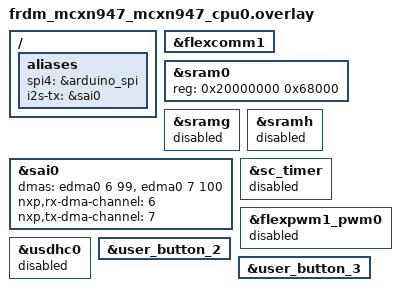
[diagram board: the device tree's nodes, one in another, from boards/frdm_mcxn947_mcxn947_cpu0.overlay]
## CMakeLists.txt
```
cmake_minimum_required(VERSION 3.20.0)
find_package(Zephyr REQUIRED HINTS $ENV{ZEPHYR_BASE})
project(zephyr_doom)

target_include_directories(app PRIVATE src/)
target_include_directories(app PRIVATE src/config)

target_sources(app PRIVATE
                src/main.c
                # Nordic-specific hardware drivers removed for portable core build:
                # src/n_qspi.c
                # src/n_fs.c
                # src/n_mem.c
                # src/n_buttons.c
                src/n_display.c
                # src/n_rjoy.c
                src/n_i2s.c
                src/n_i2s_sound.c
                src/portable_stubs.c
                src/deh_main.c
                src/deh_str.c
                src/doom/deh_misc.h
                src/doom/deh_misc.c
                src/d_event.c
                src/d_iwad.c
                src/d_mode.c
                src/d_loop.c
                src/i_timer.c
                src/i_system.c
                src/i_input.c
                src/i_video.c
                src/i_joystick.c
                src/i_sound.c
                src/m_argv.c
                src/m_bbox.c
                src/m_cheat.c
                src/m_config.c
                src/m_fixed.c
                src/m_misc.c
                src/m_controls.c
                src/net_client.c
                src/net_server.c
                src/tables.c
                src/v_diskicon.c
                src/v_video.c
                src/w_checksum.c
                src/w_file.c
                # src/w_file_fatfs.c  # disabled: usdhc0 shares pins with SAI0
                src/w_main.c
                src/w_wad.c
                src/z_native.c
                src/doom/am_map.c
                src/doom/doomstat.c
                src/doom/d_main.c
                src/doom/d_net.c
                src/doom/d_items.c
                src/doom/dstrings.c
                src/doom/f_wipe.c
                src/doom/f_finale.c
                src/doom/g_game.c
                src/doom/hu_lib.c
                src/doom/hu_stuff.c
                src/doom/info.c
                src/doom/m_menu.c
                src/doom/m_random.c
                src/doom/p_doors.c
                src/doom/p_ceilng.c
                src/doom/p_enemy.c
                src/doom/p_floor.c
                src/doom/p_lights.c
                src/doom/p_plats.c
                src/doom/p_telept.c
                src/doom/p_setup.c
                src/doom/p_sight.c
                src/doom/p_saveg.c
                src/doom/p_map.c
                src/doom/p_maputl.c
                src/doom/p_mobj.c
                src/doom/p_inter.c
                src/doom/p_tick.c
                src/doom/p_spec.c
                src/doom/p_switch.c
                src/doom/p_pspr.c
                src/doom/p_user.c
                src/doom/r_bsp.c
                src/doom/r_main.c
                src/doom/r_data.c
                src/doom/r_draw.c
                src/doom/r_plane.c
                src/doom/r_segs.c
                src/doom/r_sky.c
                src/doom/r_things.c
                src/doom/s_sound.c
                src/doom/st_lib.c
                src/doom/st_stuff.c
                src/doom/statdump.c
                src/doom/sounds.c
                src/doom/wi_stuff.c
                )


# set C version
set(CMAKE_C_STANDARD 89)

# set oldest CPP version
set(CMAKE_CXX_STANDARD  98)
```

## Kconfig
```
mainmenu "Zephyr Kernel Configuration"

# source "${ZEPHYR_BASE}/share/sysbuild/Kconfig"
source "Kconfig.zephyr"

module = DOOM_MAIN
module-str = doom_main
source "subsys/logging/Kconfig.template.log_config"

# Central UART seems to work even without this
# config NRF_DEFAULT_BLUETOOTH
# 	default y
```

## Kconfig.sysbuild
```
#
# Copyright (c) 2023 Nordic Semiconductor
#
# SPDX-License-Identifier: LicenseRef-Nordic-5-Clause
#

source "${ZEPHYR_BASE}/share/sysbuild/Kconfig"
# source "Kconfig.zephyr"

config NRF_DEFAULT_IPC_RADIO
	default y

config NETCORE_IPC_RADIO_BT_HCI_IPC
	default y
```

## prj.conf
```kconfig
## SD card filesystem disabled — usdhc0 shares pins with SAI0 (audio)
## WAD is in external flash, not on SD card
# CONFIG_DISK_DRIVERS is not set
# CONFIG_FILE_SYSTEM is not set
# CONFIG_DISK_ACCESS is not set
# CONFIG_FAT_FILESYSTEM_ELM is not set
# CONFIG_FS_FATFS_EXFAT is not set
# CONFIG_FS_FATFS_LFN is not set
# CONFIG_FS_FATFS_LFN_MODE_STACK is not set
CONFIG_SPI=y
CONFIG_GPIO=y

## Removed Nordic QSPI/XIP for portable core
# CONFIG_NRFX_QSPI is not set
CONFIG_XIP=y
# CONFIG_NORDIC_QSPI_NOR_XIP is not set
CONFIG_FLASH=y

CONFIG_MAIN_STACK_SIZE=4096

CONFIG_THREAD_RUNTIME_STATS=y
CONFIG_THREAD_RUNTIME_STATS_USE_TIMING_FUNCTIONS=y
CONFIG_TIMING_FUNCTIONS=y
CONFIG_CPU_LOAD=y
CONFIG_CPU_LOAD_LOG_PERIODICALLY=1000

CONFIG_DISPLAY=y
CONFIG_HEAP_MEM_POOL_SIZE=55000

CONFIG_SRAM_SIZE=416

## Bluetooth disabled in minimal build
# CONFIG_BT is not set

CONFIG_SYSTEM_WORKQUEUE_STACK_SIZE=2048

CONFIG_UART_INTERRUPT_DRIVEN=y
CONFIG_UART_LINE_CTRL=y

# Audio via Zephyr I2S
CONFIG_I2S=y
CONFIG_DMA_TCD_QUEUE_SIZE=4
CONFIG_LOG=y
CONFIG_LOG_MODE_IMMEDIATE=y
CONFIG_PRINTK=y
CONFIG_MAIN_THREAD_PRIORITY=4
```

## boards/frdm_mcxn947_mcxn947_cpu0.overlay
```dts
&flexcomm1 {
    status = "okay";
};

// Keep SPI DMA enabled for display performance.
// Synchronization in n_display.c ensures sync register accesses do not
// overlap with async framebuffer DMA transfers.

/ {
    aliases {
        spi4 = &arduino_spi;
        i2s-tx = &sai0;
    };
};

&sram0 {
    reg = < 0x20000000 0x68000 >;
};

&sramg {
    status = "disabled";
};

&sramh {
    status = "disabled";
};

/* I2S audio via SAI0 → PCM5102 DAC.
 * SAI0 pins: TXD0=PIO2_2, TX_BCLK=PIO2_6, TX_FS=PIO2_7.
 * These pins conflict with sc_timer, flexpwm1_pwm0, and usdhc0.
 * Also move SAI0 onto dedicated EDMA channels so it does not collide with
 * the display SPI DMA channels used by arduino_spi. */
&sai0 {
    status = "okay";
    dmas = <&edma0 6 99>, <&edma0 7 100>;
    dma-names = "rx", "tx";
    nxp,rx-dma-channel = <6>;
    nxp,tx-dma-channel = <7>;
};

&sc_timer {
    status = "disabled";
};

&flexpwm1_pwm0 {
    status = "disabled";
};

&usdhc0 {
    status = "disabled";
};

&user_button_2 {
    status = "okay";
};

&user_button_3 {
    status = "okay";
};
```

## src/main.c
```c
/*
 * Copyright (c) 2016 Intel Corporation
 *
 * SPDX-License-Identifier: Apache-2.0
 */

#ifdef CONFIG_FAT_FILESYSTEM_ELM
#include <ff.h>
#endif
#include <string.h>
#include <zephyr/device.h>
#include <zephyr/devicetree.h>
#include <zephyr/drivers/gpio.h>
#ifdef CONFIG_FAT_FILESYSTEM_ELM
#include <zephyr/fs/fs.h>
#endif
#include <zephyr/kernel.h>
#include <zephyr/logging/log.h>
// #include <zephyr/sd/sd.h>
#include <zephyr/storage/disk_access.h>

#include <zephyr/debug/cpu_load.h>

#include <zephyr/sys/printk.h>

extern uint32_t SystemCoreClock;

LOG_MODULE_REGISTER(doom_main, CONFIG_DOOM_MAIN_LOG_LEVEL);

/* Bluetooth control disabled in portable core build */

/* Forward declarations from original headers to avoid pulling Nordic-specific
 * dependencies */
void N_ButtonsInit(void);
void N_I2S_init(void);
void M_ArgvInit(void);
void D_DoomMain(void);

/* 1000 msec = 1 sec */
#define SLEEP_TIME_MS 1000

/* LED access not used in minimal build */

#define SD_ROOT_PATH "/SD:/"
#ifdef CONFIG_FAT_FILESYSTEM_ELM
/* Maximum length for path support by Windows file system */
#define PATH_MAX_LEN 260
#define K_SEM_OPER_TIMEOUT_MS 500
K_SEM_DEFINE(m_sem_sd_oper_ongoing, 1, 1);

void clock_initialization() { /* No-op for portable build */ }

static const char* sd_root_path = "/SD:";
static bool sd_init_success;

static FATFS fat_fs;

static struct fs_mount_t mnt_pt = {
    .type = FS_FATFS,
    .fs_data = &fat_fs,
};

int sd_card_init(void) {
    int ret;
    static const char* sd_dev = "SD";
    uint64_t sd_card_size_bytes;
    uint32_t sector_count;
    size_t sector_size;

    ret = disk_access_init(sd_dev);
    if (ret) {
        LOG_DBG("SD card init failed, please check if SD card inserted");
        return -ENODEV;
    }

    ret = disk_access_ioctl(sd_dev, DISK_IOCTL_GET_SECTOR_COUNT, &sector_count);
    if (ret) {
        LOG_ERR("Unable to get sector count");
        return ret;
    }

    LOG_DBG("Sector count: %d", sector_count);

    ret = disk_access_ioctl(sd_dev, DISK_IOCTL_GET_SECTOR_SIZE, &sector_size);
    if (ret) {
        LOG_ERR("Unable to get sector size");
        return ret;
    }

    LOG_DBG("Sector size: %d bytes", sector_size);

    sd_card_size_bytes = (uint64_t)sector_count * sector_size;

    LOG_INF("SD card volume size: %d MB", (uint32_t)(sd_card_size_bytes >> 20));

    mnt_pt.mnt_point = sd_root_path;

    ret = fs_mount(&mnt_pt);
    if (ret) {
        LOG_ERR("Mnt. disk failed, could be format issue. should be FAT/exFAT");
        return ret;
    }

    sd_init_success = true;

    return 0;
}

int sd_card_list_files(char const* const path, char* buf, size_t* buf_size) {
    int ret;
    struct fs_dir_t dirp;
    static struct fs_dirent entry;
    char abs_path_name[PATH_MAX_LEN + 1] = SD_ROOT_PATH;
    size_t used_buf_size = 0;

    if (k_sem_count_get(&m_sem_sd_oper_ongoing) <= 0) {
        LOG_ERR("SD operation ongoing");
        return -EPERM;
    }

    k_sem_take(&m_sem_sd_oper_ongoing, K_MSEC(K_SEM_OPER_TIMEOUT_MS));

    if (!sd_init_success) {
        k_sem_give(&m_sem_sd_oper_ongoing);
        return -ENODEV;
    }

    fs_dir_t_init(&dirp);

    if (path == NULL) {
        ret = fs_opendir(&dirp, sd_root_path);
        if (ret) {
            LOG_ERR("Open SD card root dir failed");
            k_sem_give(&m_sem_sd_oper_ongoing);
            return ret;
        }
    } else {
        if (strlen(path) > CONFIG_FS_FATFS_MAX_LFN) {
            LOG_ERR("Path is too long");
            k_sem_give(&m_sem_sd_oper_ongoing);
            // return -FR_INVALID_NAME;
            return -1;
        }

        strcat(abs_path_name, path);

        ret = fs_opendir(&dirp, abs_path_name);
        if (ret) {
            LOG_ERR("Open assigned path failed");
            k_sem_give(&m_sem_sd_oper_ongoing);
            return ret;
        }
    }

    while (1) {
        ret = fs_readdir(&dirp, &entry);
        if (ret) {
            k_sem_give(&m_sem_sd_oper_ongoing);
            return ret;
        }

        if (entry.name[0] == 0) {
            break;
        }

        if (buf != NULL) {
            size_t remaining_buf_size = *buf_size - used_buf_size;
            ssize_t len = snprintk(
                &buf[used_buf_size], remaining_buf_size, "[%s]\t%s\n",
                entry.type == FS_DIR_ENTRY_DIR ? "DIR " : "FILE", entry.name);

            if (len >= remaining_buf_size) {
                LOG_ERR("Failed to append to buffer, error: %d", len);
                k_sem_give(&m_sem_sd_oper_ongoing);
                return -EINVAL;
            }

            used_buf_size += len;
        }

        LOG_INF("[%s] %s", entry.type == FS_DIR_ENTRY_DIR ? "DIR " : "FILE",
                entry.name);
    }

    ret = fs_closedir(&dirp);
    if (ret) {
        LOG_ERR("Close SD card root dir failed");
        k_sem_give(&m_sem_sd_oper_ongoing);
        return ret;
    }

    *buf_size = used_buf_size;
    k_sem_give(&m_sem_sd_oper_ongoing);
    return 0;
}
#else
void clock_initialization() { /* No-op for portable build */ }
#endif /* CONFIG_FAT_FILESYSTEM_ELM */

int main(void) {
    LOG_INF("BOARD STARTING %s", CONFIG_BOARD);

    printk("CPU clock: %u Hz\n", SystemCoreClock);


    /* Minimal portable initialization */
    N_ButtonsInit();
    N_I2S_init();
    M_ArgvInit();

    /* Start DOOM */
    D_DoomMain();

    /* Idle forever */
    for (;;) {
        k_sleep(K_MSEC(SLEEP_TIME_MS));
    }

    return 0;
}
```

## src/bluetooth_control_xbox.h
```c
/* main.c - Application main entry point */

/*
 * Copyright (c) 2018 Nordic Semiconductor ASA
 *
 * SPDX-License-Identifier: LicenseRef-Nordic-5-Clause
 */

#include <bluetooth/gatt_dm.h>
#include <bluetooth/scan.h>
#include <bluetooth/services/hogp.h>
#include <errno.h>
#include <stddef.h>
#include <stdint.h>
#include <zephyr/bluetooth/bluetooth.h>
#include <zephyr/bluetooth/conn.h>
#include <zephyr/bluetooth/gatt.h>
#include <zephyr/bluetooth/hci.h>
#include <zephyr/bluetooth/uuid.h>
#include <zephyr/devicetree.h>
#include <zephyr/drivers/gpio.h>
#include <zephyr/kernel.h>
#include <zephyr/logging/log.h>
#include <zephyr/settings/settings.h>
#include <zephyr/sys/byteorder.h>
#include <zephyr/sys/printk.h>
#include <zephyr/types.h>

#include "d_event.h"
#include "m_controls.h"

#define RESET_TIMEOUT_MS 500

#define DEADZONE_X 8
#define DEADZONE_Y 8

static struct k_work_delayable reset_work;
static void reset_inputs(struct k_work *work) {
    printk("Resetting joystick and button states\n");

    event_t joystick_event;
    joystick_event.type = ev_joystick;
    joystick_event.data1 = 0;  // No buttons pressed
    joystick_event.data2 = 0;  // Joystick X reset
    joystick_event.data3 = 0;  // Joystick Y reset

    D_PostEvent(&joystick_event);
}

#define SW0_NODE DT_ALIAS(sw0)
static const struct gpio_dt_spec button =
    GPIO_DT_SPEC_GET_OR(SW0_NODE, gpios, {0});

static struct gpio_callback button_cb_data;
static struct bt_conn *default_conn;
static struct bt_hogp hogp;
static struct bt_conn *auth_conn;

static void hids_on_ready(struct k_work *work);
static K_WORK_DEFINE(hids_ready_work, hids_on_ready);

extern struct bt_gatt_dm {
    /* Connection object */
    struct bt_conn *conn;
    /* The user context */
    void *context;

    /* The discovery parameters used */
    struct bt_gatt_discover_params discover_params;
    /* Currently parsed attributes */
    struct bt_gatt_dm_attr attrs[CONFIG_BT_GATT_DM_MAX_ATTRS];
    /* Currently accessed attribute */
    size_t cur_attr_id;
    /* Flags with the status of the attributes */
    // ATOMIC_DEFINE(state_flags, STATE_NUM);

    /* The UUID of the service to discover. */
    union {
        struct bt_uuid uuid;
        struct bt_uuid_16 u16;
        struct bt_uuid_32 u32;
        struct bt_uuid_128 u128;
    } svc_uuid;

    /* Single-linked list of allocated chunks for user data */
    sys_slist_t chunk_list;
    /* The used length of the current chunk */
    size_t cur_chunk_len;

    /* The pointer to callback structure */
    const struct bt_gatt_dm_cb *callback;

    /* Indicates that services should be searched by the UUID. */
    bool search_svc_by_uuid;
};

static void scan_filter_match(struct bt_scan_device_info *device_info,
                              struct bt_scan_filter_match *filter_match,
                              bool connectable) {
    char addr[BT_ADDR_LE_STR_LEN];

    if (!filter_match->uuid.match || (filter_match->uuid.count != 1)) {
        printk("Invalid device connected\n");

        return;
    }

    const struct bt_uuid *uuid = filter_match->uuid.uuid[0];

    bt_addr_le_to_str(device_info->recv_info->addr, addr, sizeof(addr));

    printk("Filters matched on UUID 0x%04x.\nAddress: %s connectable: %s\n",
           BT_UUID_16(uuid)->val, addr, connectable ? "yes" : "no");
}

static void scan_connecting_error(struct bt_scan_device_info *device_info) {
    printk("Connecting failed\n");
}

static void scan_connecting(struct bt_scan_device_info *device_info,
                            struct bt_conn *conn) {
    default_conn = bt_conn_ref(conn);
}
/** .. include_startingpoint_scan_rst */
static void scan_filter_no_match(struct bt_scan_device_info *device_info,
                                 bool connectable) {
    int err;
    struct bt_conn *conn;
    char addr[BT_ADDR_LE_STR_LEN];

    if (device_info->recv_info->adv_type == BT_GAP_ADV_TYPE_ADV_DIRECT_IND) {
        bt_addr_le_to_str(device_info->recv_info->addr, addr, sizeof(addr));
        printk("Direct advertising received from %s\n", addr);
        bt_scan_stop();

        err = bt_conn_le_create(device_info->recv_info->addr,
                                BT_CONN_LE_CREATE_CONN, device_info->conn_param,
                                &conn);

        if (!err) {
            default_conn = bt_conn_ref(conn);
            bt_conn_unref(conn);
        }
    }
}
/** .. include_endpoint_scan_rst */
BT_SCAN_CB_INIT(scan_cb, scan_filter_match, scan_filter_no_match,
                scan_connecting_error, scan_connecting);

// for XBOX Gamepad
void convert_uuid128_to_uuid16_services(struct bt_gatt_dm *dm) {
    char str[37];
    int i = 0;

    while (dm->attrs[i + 1].handle != 0x0000) {
        if (!bt_uuid_cmp(dm->attrs[i].uuid,
                         BT_UUID_DECLARE_128(BT_UUID_128_ENCODE(
                             BT_UUID_HIDS_INFO_VAL, 0, 0, 0, 0)))) {
            dm->attrs[i].uuid->type = BT_UUID_TYPE_16;
            BT_UUID_16(dm->attrs[i].uuid)->val = BT_UUID_HIDS_INFO_VAL;
        }

        else if (!bt_uuid_cmp(dm->attrs[i].uuid,
                              BT_UUID_DECLARE_128(BT_UUID_128_ENCODE(
                                  BT_UUID_HIDS_CTRL_POINT_VAL, 0, 0, 0, 0)))) {
            dm->attrs[i].uuid->type = BT_UUID_TYPE_16;
            BT_UUID_16(dm->attrs[i].uuid)->val = BT_UUID_HIDS_CTRL_POINT_VAL;
        }

        else if (!bt_uuid_cmp(dm->attrs[i].uuid,
                              BT_UUID_DECLARE_128(BT_UUID_128_ENCODE(
                                  BT_UUID_HIDS_REPORT_MAP_VAL, 0, 0, 0, 0)))) {
            dm->attrs[i].uuid->type = BT_UUID_TYPE_16;
            BT_UUID_16(dm->attrs[i].uuid)->val = BT_UUID_HIDS_REPORT_MAP_VAL;
        }

        else if (!bt_uuid_cmp(dm->attrs[i].uuid,
                              BT_UUID_DECLARE_128(BT_UUID_128_ENCODE(
                                  BT_UUID_HIDS_REPORT_VAL, 0, 0, 0, 0)))) {
            dm->attrs[i].uuid->type = BT_UUID_TYPE_16;
            BT_UUID_16(dm->attrs[i].uuid)->val = BT_UUID_HIDS_REPORT_VAL;
            BT_UUID_16(dm->attrs[11].uuid)->val =
                BT_UUID_HIDS_REPORT_VAL;  // hardcoded for XBOX
        }

        bt_uuid_to_str(dm->attrs[i].uuid, str, sizeof(str));
        printk("\tUUID[%d]: 0x%s\t\n", i, str);

        i++;
    }
}

static void discovery_completed_cb(struct bt_gatt_dm *dm, void *context) {
    int err;

    printk("The discovery procedure succeeded\n");
    printk(
        "\nFor XBOX controllers, you need to manually exit pairing mode or "
        "wait for the timeout\n\n");

    convert_uuid128_to_uuid16_services(
        dm);  // need convert some UUID128 into UUID16 (for XBOX Controller)

    bt_gatt_dm_data_print(dm);

    err = bt_hogp_handles_assign(dm, &hogp);

    if (err) {
        printk("Could not init HIDS client object, error: %d\n", err);
    }

    err = bt_gatt_dm_data_release(dm);
    if (err) {
        printk(
            "Could not release the discovery data, error "
            "code: %d\n",
            err);
    }
}

static void discovery_service_not_found_cb(struct bt_conn *conn,
                                           void *context) {
    printk("The service could not be found during the discovery\n");
}

static void discovery_error_found_cb(struct bt_conn *conn, int err,
                                     void *context) {
    printk("The discovery procedure failed with %d\n", err);
}

static const struct bt_gatt_dm_cb discovery_cb = {
    .completed = discovery_completed_cb,
    .service_not_found = discovery_service_not_found_cb,
    .error_found = discovery_error_found_cb,
};

static void gatt_discover(struct bt_conn *conn) {
    int err;

    if (conn != default_conn) {
        return;
    }

    err = bt_gatt_dm_start(conn, BT_UUID_HIDS, &discovery_cb, NULL);
    if (err) {
        printk(
            "could not start the discovery procedure, error "
            "code: %d\n",
            err);
    }
}

static void connected(struct bt_conn *conn, uint8_t conn_err) {
    int err;
    char addr[BT_ADDR_LE_STR_LEN];

    bt_addr_le_to_str(bt_conn_get_dst(conn), addr, sizeof(addr));

    if (conn_err) {
        printk("Failed to connect to %s (%u)\n", addr, conn_err);
        if (conn == default_conn) {
            bt_conn_unref(default_conn);
            default_conn = NULL;

            /* This demo doesn't require active scan */
            err = bt_scan_start(BT_SCAN_TYPE_SCAN_ACTIVE);
            if (err) {
                printk("Scanning failed to start (err %d)\n", err);
            }
        }

        return;
    }

    printk("Connected: %s\n", addr);

    err = bt_conn_set_security(conn, BT_SECURITY_L2);
    if (err) {
        printk("Failed to set security: %d\n", err);

        gatt_discover(conn);
    }
}

static void disconnected(struct bt_conn *conn, uint8_t reason) {
    char addr[BT_ADDR_LE_STR_LEN];
    int err;

    bt_addr_le_to_str(bt_conn_get_dst(conn), addr, sizeof(addr));

    if (auth_conn) {
        bt_conn_unref(auth_conn);
        auth_conn = NULL;
    }

    printk("Disconnected: %s (reason %u)\n", addr, reason);

    if (bt_hogp_assign_check(&hogp)) {
        printk("HIDS client active - releasing");
        bt_hogp_release(&hogp);
    }

    if (default_conn != conn) {
        return;
    }

    bt_conn_unref(default_conn);
    default_conn = NULL;

    /* This demo doesn't require active scan */
    err = bt_scan_start(BT_SCAN_TYPE_SCAN_ACTIVE);
    if (err) {
        printk("Scanning failed to start (err %d)\n", err);
    }
}

static void security_changed(struct bt_conn *conn, bt_security_t level,
                             enum bt_security_err err) {
    char addr[BT_ADDR_LE_STR_LEN];

    bt_addr_le_to_str(bt_conn_get_dst(conn), addr, sizeof(addr));

    if (!err) {
        printk("Security changed: %s level %u\n", addr, level);
    } else {
        printk("Security failed: %s level %u err %d\n", addr, level, err);
    }

    gatt_discover(conn);
}

BT_CONN_CB_DEFINE(conn_callbacks) = {.connected = connected,
                                     .disconnected = disconnected,
                                     .security_changed = security_changed};

static void scan_init(void) {
    int err;

    struct bt_scan_init_param scan_init = {
        .connect_if_match = 1,
        .scan_param = NULL,
        .conn_param = BT_LE_CONN_PARAM_DEFAULT};

    bt_scan_init(&scan_init);
    bt_scan_cb_register(&scan_cb);

    err = bt_scan_filter_add(BT_SCAN_FILTER_TYPE_UUID, BT_UUID_HIDS);
    if (err) {
        printk("Scanning filters cannot be set (err %d)\n", err);

        return;
    }

    err = bt_scan_filter_enable(BT_SCAN_UUID_FILTER, false);
    if (err) {
        printk("Filters cannot be turned on (err %d)\n", err);
    }
}

static uint8_t hogp_notify_cb(struct bt_hogp *hogp,
                              struct bt_hogp_rep_info *rep, uint8_t err,
                              const uint8_t *data) {
    static bool prev_dpad_up = false;
    static bool prev_dpad_down = false;
    static bool prev_button_back = false;
    static bool prev_button_start = false;
    static event_t prev_joystick_event;

    if (!data) {
        return BT_GATT_ITER_STOP;
    }

    // uint8_t size = bt_hogp_rep_size(rep);
    // uint8_t i;
    // printk("Notification, id: %u, size: %u, data:", bt_hogp_rep_id(rep), size);

    // for (i = 0; i < size; ++i) {
    //     printk(" 0x%x", data[i]);
    // }
    // printk("\n");

    event_t joystick_event;
    event_t keyboard_event;
    joystick_event.type = ev_joystick;
    keyboard_event.type = ev_keydown;

    bool dpad_up = data[12] == 0x01;
    bool dpad_down = data[12] == 0x05;
    bool button_A = data[13] == 0x01;
    bool button_B = data[13] == 0x02;
    bool button_X = data[13] == 0x08;
    bool button_Y = data[13] == 0x10;
    bool button_back = data[14] == 0x04;
    bool button_start = data[14] == 0x08;
    joystick_event.data1 =
        (button_A << 4) | (button_B << 5) | (button_X << 2) | (button_Y << 3);

    // Left joystick used for movement and turning
    int32_t leftJoyX = (data[1] << 8 | data[0]);
    int32_t leftJoyY = (data[3] << 8 | data[2]);

    leftJoyX = ((leftJoyX - 32767) / (double)32767) * 65;
    leftJoyY = ((leftJoyY - 32767) / (double)32767) * 65;
    if (leftJoyX > -DEADZONE_X && leftJoyX < DEADZONE_X) {
        leftJoyX = 0;
    }
    if (leftJoyY > -DEADZONE_Y && leftJoyY < DEADZONE_Y) {
        leftJoyY = 0;
    }

    joystick_event.data2 = leftJoyX;
    joystick_event.data3 = leftJoyY;

    // Used for strafing
    int16_t LT = data[8];
    int16_t RT = data[10];

    if (LT > 5) {
        joystick_event.data4 = -LT;
    } else if (RT > 5) {
        joystick_event.data4 = RT;
    } else {
        joystick_event.data4 = 0;
    }

    if (joystick_event.data1 != prev_joystick_event.data1 ||
        joystick_event.data2 != prev_joystick_event.data2 ||
        joystick_event.data3 != prev_joystick_event.data3 ||
        joystick_event.data4 != prev_joystick_event.data4 ||
        joystick_event.data5 != prev_joystick_event.data5) {
        D_PostEvent(&joystick_event);
        prev_joystick_event = joystick_event;
    }
    if (dpad_up && !prev_dpad_up) {
        keyboard_event.data1 = key_up;
        D_PostEvent(&keyboard_event);
    }
    if (dpad_down && !prev_dpad_down) {
        keyboard_event.data1 = key_down;
        D_PostEvent(&keyboard_event);
    }
    if (button_back && !prev_button_back) {
        keyboard_event.data1 = key_map_toggle;
        D_PostEvent(&keyboard_event);
    }
    if (button_start && !prev_button_start) {
        keyboard_event.data1 = key_menu_activate;
        D_PostEvent(&keyboard_event);
    }

    prev_dpad_up = dpad_up;
    prev_dpad_down = dpad_down;
    prev_button_back = button_back;
    prev_button_start = button_start;

    // k_work_reschedule(&reset_work, K_MSEC(RESET_TIMEOUT_MS));

    return BT_GATT_ITER_CONTINUE;
}

static void hogp_ready_cb(struct bt_hogp *hogp) {
    k_work_submit(&hids_ready_work);
}

static void hids_on_ready(struct k_work *work) {
    int err;
    struct bt_hogp_rep_info *rep = NULL;

    printk("HIDS is ready to work\n");

    while (NULL != (rep = bt_hogp_rep_next(&hogp, rep))) {
        if (bt_hogp_rep_type(rep) == BT_HIDS_REPORT_TYPE_INPUT) {
            printk("Subscribe to report id: %u\n", bt_hogp_rep_id(rep));
            err = bt_hogp_rep_subscribe(&hogp, rep, hogp_notify_cb);
            if (err) {
                printk("Subscribe error (%d)\n", err);
            }
        }
    }
}

static void hogp_prep_fail_cb(struct bt_hogp *hogp, int err) {
    printk("ERROR: HIDS client preparation failed!\n");
}

/* HIDS client initialization parameters */
static const struct bt_hogp_init_params hogp_init_params = {
    .ready_cb = hogp_ready_cb,
    .prep_error_cb = hogp_prep_fail_cb,
};

void button_pressed(const struct device *dev, struct gpio_callback *cb,
                    uint32_t pins) {
    printk("Button Pressed\n");

    if (auth_conn) {
        bt_conn_auth_passkey_confirm(auth_conn);
        printk("Numeric Match, conn %p\n", auth_conn);
    }

    return;
}

static void auth_passkey_display(struct bt_conn *conn, unsigned int passkey) {
    char addr[BT_ADDR_LE_STR_LEN];

    bt_addr_le_to_str(bt_conn_get_dst(conn), addr, sizeof(addr));

    printk("Passkey for %s: %06u\n", addr, passkey);
}

static void auth_passkey_confirm(struct bt_conn *conn, unsigned int passkey) {
    char addr[BT_ADDR_LE_STR_LEN];

    auth_conn = bt_conn_ref(conn);

    bt_addr_le_to_str(bt_conn_get_dst(conn), addr, sizeof(addr));

    printk("Passkey for %s: %06u\n", addr, passkey);
    printk("Press Button 1 to confirm, Button 2 to reject.\n");
}

static void auth_cancel(struct bt_conn *conn) {
    char addr[BT_ADDR_LE_STR_LEN];

    bt_addr_le_to_str(bt_conn_get_dst(conn), addr, sizeof(addr));

    printk("Pairing cancelled: %s\n", addr);
}

static void pairing_complete(struct bt_conn *conn, bool bonded) {
    char addr[BT_ADDR_LE_STR_LEN];

    bt_addr_le_to_str(bt_conn_get_dst(conn), addr, sizeof(addr));

    printk("Pairing completed: %s, bonded: %d\n", addr, bonded);
}

static void pairing_failed(struct bt_conn *conn, enum bt_security_err reason) {
    char addr[BT_ADDR_LE_STR_LEN];

    bt_addr_le_to_str(bt_conn_get_dst(conn), addr, sizeof(addr));

    printk("Pairing failed conn: %s, reason %d\n", addr, reason);
}

static struct bt_conn_auth_cb conn_auth_callbacks = {
    .passkey_display = auth_passkey_display,
    .passkey_confirm = auth_passkey_confirm,
    .cancel = auth_cancel,
};

static struct bt_conn_auth_info_cb conn_auth_info_callbacks = {
    .pairing_complete = pairing_complete, .pairing_failed = pairing_failed};

int bluetooth_main_xbox(void) {
    int err;

    printk("Starting Bluetooth Central HIDS example\n");

    bt_hogp_init(&hogp, &hogp_init_params);

    err = bt_conn_auth_cb_register(&conn_auth_callbacks);
    if (err) {
        printk("failed to register authorization callbacks.\n");
        return 0;
    }

    err = bt_conn_auth_info_cb_register(&conn_auth_info_callbacks);
    if (err) {
        printk("Failed to register authorization info callbacks.\n");
        return 0;
    }

    err = bt_enable(NULL);
    if (err) {
        printk("Bluetooth init failed (err %d)\n", err);
        return 0;
    }

    printk("Bluetooth initialized\n");

    // if (IS_ENABLED(CONFIG_SETTINGS)) {
    //     settings_load();
    // }

    scan_init();

    if (!gpio_is_ready_dt(&button)) {
        printk("Error: button device %s is not ready\n", button.port->name);
        return 0;
    }

    err = gpio_pin_configure_dt(&button, GPIO_INPUT);
    if (err != 0) {
        printk("Error %d: failed to configure %s pin %d\n", err,
               button.port->name, button.pin);
        return 0;
    }

    err = gpio_pin_interrupt_configure_dt(&button, GPIO_INT_EDGE_TO_ACTIVE);
    if (err != 0) {
        printk("Error %d: failed to configure interrupt on %s pin %d\n", err,
               button.port->name, button.pin);
        return 0;
    }

    gpio_init_callback(&button_cb_data, button_pressed, BIT(button.pin));
    gpio_add_callback(button.port, &button_cb_data);

    k_work_init_delayable(&reset_work, reset_inputs);

    err = bt_scan_start(BT_SCAN_TYPE_SCAN_ACTIVE);
    if (err) {
        printk("Scanning failed to start (err %d)\n", err);
        return 0;
    }

    printk("Scanning successfully started\n");

    return 0;
}
```

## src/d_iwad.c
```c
//
// Copyright(C) 2005-2014 Simon Howard
//
// This program is free software; you can redistribute it and/or
// modify it under the terms of the GNU General Public License
// as published by the Free Software Foundation; either version 2
// of the License, or (at your option) any later version.
//
// This program is distributed in the hope that it will be useful,
// but WITHOUT ANY WARRANTY; without even the implied warranty of
// MERCHANTABILITY or FITNESS FOR A PARTICULAR PURPOSE.  See the
// GNU General Public License for more details.
//
// DESCRIPTION:
//     Search for and locate an IWAD file, and initialize according
//     to the IWAD type.
//

#include <stdio.h>
#include <stdlib.h>
#include <ctype.h>
#include <string.h>
#ifndef SEGGER
#include <strings.h>
#endif

#include "deh_str.h"
#include "doomkeys.h"
#include "d_iwad.h"
#include "i_system.h"
#include "m_argv.h"
#include "m_config.h"
#include "m_misc.h"
#include "w_wad.h"
#include "z_zone.h"

#include "n_mem.h"
#include "n_fs.h"

static const iwad_t iwads[] =
{
    { "doom.wad",     doom,      retail,     "Doom" },
    { "doom1.wad",    doom,      shareware,  "Doom Shareware" },
    { "doom2.wad",    doom2,     commercial, "Doom II" },
    /*
    { "plutonia.wad", pack_plut, commercial, "Final Doom: Plutonia Experiment" },
    { "tnt.wad",      pack_tnt,  commercial, "Final Doom: TNT: Evilution" },
    { "chex.wad",     pack_chex, retail,     "Chex Quest" },
    { "hacx.wad",     pack_hacx, commercial, "Hacx" },
    { "freedm.wad",   doom2,     commercial, "FreeDM" },
    { "freedoom2.wad", doom2,    commercial, "Freedoom: Phase 2" },
    { "freedoom1.wad", doom,     retail,     "Freedoom: Phase 1" },
    { "heretic.wad",  heretic,   retail,     "Heretic" },
    { "heretic1.wad", heretic,   shareware,  "Heretic Shareware" },
    { "hexen.wad",    hexen,     commercial, "Hexen" },
    //{ "strife0.wad",  strife,    commercial, "Strife" }, // haleyjd: STRIFE-FIXME
    { "strife1.wad",  strife,    commercial, "Strife" },*/
};

// Array of locations to search for IWAD files
//
// "128 IWAD search directories should be enough for anybody".

/* NRFD-TODO?
#define MAX_IWAD_DIRS 128

static boolean iwad_dirs_built = false;
static char *iwad_dirs[MAX_IWAD_DIRS];
static int num_iwad_dirs = 0;
*/

static void AddIWADDir(char *dir)
{
    /* NRFD_TODO?
    if (num_iwad_dirs < MAX_IWAD_DIRS)
    {
        iwad_dirs[num_iwad_dirs] = dir;
        ++num_iwad_dirs;
    }
    */
}


// Check if the specified directory contains the specified IWAD
// file, returning the full path to the IWAD if found, or NULL
// if not found.

static char *CheckDirectoryHasIWAD(char *dir, char *iwadname)
{
    char *filename;
    char *probe;

    // As a special case, the "directory" may refer directly to an
    // IWAD file if the path comes from DOOMWADDIR or DOOMWADPATH.

    // probe = M_FileCaseExists(dir);
    // if (DirIsFile(dir, iwadname) && probe != NULL)
    // {
    //     return probe;
    // }

    // Construct the full path to the IWAD if it is located in
    // this directory, and check if it exists.

/* NRFD-TODO?
    if (!strcmp(dir, "."))
    {
        filename = M_StringDuplicate(iwadname);
    }
    else
    {
        filename = M_StringJoin(dir, DIR_SEPARATOR_S, iwadname, NULL);
    }

    probe = M_FileCaseExists(filename);
    if (probe != NULL)
    {
        return probe;
    }

    free(filename);
    */
    probe = M_FileCaseExists(iwadname);
    if (probe != NULL)
    {
        return probe;
    }

    return NULL;
}

// Search a directory to try to find an IWAD
// Returns the location of the IWAD if found, otherwise NULL.

static char *SearchDirectoryForIWAD(char *dir, int mask, GameMission_t *mission)
{
    char *filename;
    size_t i;

    for (i=0; i<arrlen(iwads); ++i)
    {
        if (((1 << iwads[i].mission) & mask) == 0)
        {
            continue;
        }

        filename = CheckDirectoryHasIWAD(dir, DEH_String(iwads[i].name));

        if (filename != NULL)
        {
            *mission = iwads[i].mission;

            return filename;
        }
    }

    return NULL;
}

// When given an IWAD with the '-iwad' parameter,
// attempt to identify it by its name.

static GameMission_t IdentifyIWADByName(char *name, int mask)
{
    size_t i;
    GameMission_t mission;
    char *p;

    p = strrchr(name, DIR_SEPARATOR);

    if (p != NULL)
    {
        name = p + 1;
    }

    mission = none;

    for (i=0; i<arrlen(iwads); ++i)
    {
        // Check if the filename is this IWAD name.

        // Only use supported missions:

        if (((1 << iwads[i].mission) & mask) == 0)
            continue;

        // Check if it ends in this IWAD name.

        if (!strcasecmp(name, iwads[i].name))
        {
            mission = iwads[i].mission;
            break;
        }
    }

    return mission;
}


//
// Build a list of IWAD files
//

static void BuildIWADDirList(void)
{
    return; /* NRFD-TODO?
    char *env;

    if (iwad_dirs_built)
    {
        return;
    }

    // Only look in root
    AddIWADDir("");
    */

}

//
// Searches WAD search paths for an WAD with a specific filename.
//
char *D_FindWADByName(char *name)
{
    char *path;
    char *probe;
    int i;

    // Absolute path?

    probe = M_FileCaseExists(name);
    if (probe != NULL)
    {
        return probe;
    }

    BuildIWADDirList();

    // Search through all IWAD paths for a file with the given name.
    /* NRFD-TODO?
    for (i=0; i<num_iwad_dirs; ++i)
    {
        // As a special case, if this is in DOOMWADDIR or DOOMWADPATH,
        // the "directory" may actually refer directly to an IWAD
        // file.
        probe = M_FileCaseExists(iwad_dirs[i]);
        if (DirIsFile(iwad_dirs[i], name) && probe != NULL)
        {
            return probe;
        }

        // Construct a string for the full path

        path = M_StringJoin(iwad_dirs[i], DIR_SEPARATOR_S, name, NULL);

        probe = M_FileCaseExists(path);
        if (probe != NULL)
        {
            return probe;
        }

        free(path);
    }
    */

    probe = M_FileCaseExists(name);
    if (probe != NULL)
    {
        return probe;
    }


    // File not found
    return NULL;
}

//
// D_TryWADByName
//
// Searches for a WAD by its filename, or passes through the filename
// if not found.
//

char *D_TryFindWADByName(char *filename)
{
    char *result;

    result = D_FindWADByName(filename);

    if (result != NULL)
    {
        return result;
    }
    else
    {
        return filename;
    }
}

//
// FindIWAD
// Checks availability of IWAD files by name,
// to determine whether registered/commercial features
// should be executed (notably loading PWADs).
//

char *D_FindIWAD(int mask, GameMission_t *mission)
{
    char *result;
    char *iwadfile;
    int iwadparm;
    int i;

    // Check for the -iwad parameter

    //!
    // Specify an IWAD file to use.
    //
    // @arg <file>
    //

    iwadparm = M_CheckParmWithArgs("-iwad", 1);

    if (iwadparm)
    {
        // Search through IWAD dirs for an IWAD with the given name.

        iwadfile = myargv[iwadparm + 1];

        result = D_FindWADByName(iwadfile);

        if (result == NULL)
        {
            I_Error("IWAD file '%s' not found!", iwadfile);
        }

        *mission = IdentifyIWADByName(result, mask);
    }
    else
    {
        // Search through the list and look for an IWAD

        result = NULL;

        /* NRFD-TODO?
        BuildIWADDirList();

        for (i=0; result == NULL && i<num_iwad_dirs; ++i)
        {
            result = SearchDirectoryForIWAD(iwad_dirs[i], mask, mission);
        }
        */
        result = SearchDirectoryForIWAD("", mask, mission);
    }

    return result;
}

// Find all IWADs in the IWAD search path matching the given mask.

const iwad_t **D_FindAllIWADs(int mask)
{
    const iwad_t **result;
    int result_len;
    char *filename;
    int i;

    result = N_malloc(sizeof(iwad_t *) * (arrlen(iwads) + 1));
    result_len = 0;

    // Try to find all IWADs

    for (i=0; i<arrlen(iwads); ++i)
    {
        if (((1 << iwads[i].mission) & mask) == 0)
        {
            continue;
        }

        filename = D_FindWADByName(iwads[i].name);

        if (filename != NULL)
        {
            result[result_len] = &iwads[i];
            ++result_len;
        }
    }

    // End of list

    result[result_len] = NULL;

    return result;
}

//
// Get the IWAD name used for savegames.
//

char *D_SaveGameIWADName(GameMission_t gamemission)
{
    size_t i;

    // Determine the IWAD name to use for savegames.
    // This determines the directory the savegame files get put into.
    //
    // Note that we match on gamemission rather than on IWAD name.
    // This ensures that doom1.wad and doom.wad saves are stored
    // in the same place.

    for (i=0; i<arrlen(iwads); ++i)
    {
        if (gamemission == iwads[i].mission)
        {
            return iwads[i].name;
        }
    }

    // Default fallback:

    return "unknown.wad";
}

char *D_SuggestIWADName(GameMission_t mission, GameMode_t mode)
{
    int i;

    for (i = 0; i < arrlen(iwads); ++i)
    {
        if (iwads[i].mission == mission && iwads[i].mode == mode)
        {
            return iwads[i].name;
        }
    }

    return "unknown.wad";
}

char *D_SuggestGameName(GameMission_t mission, GameMode_t mode)
{
    int i;

    for (i = 0; i < arrlen(iwads); ++i)
    {
        if (iwads[i].mission == mission
         && (mode == indetermined || iwads[i].mode == mode))
        {
            return iwads[i].description;
        }
    }

    return "Unknown game?";
}
```

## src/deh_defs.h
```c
//
// Copyright(C) 2005-2014 Simon Howard
//
// This program is free software; you can redistribute it and/or
// modify it under the terms of the GNU General Public License
// as published by the Free Software Foundation; either version 2
// of the License, or (at your option) any later version.
//
// This program is distributed in the hope that it will be useful,
// but WITHOUT ANY WARRANTY; without even the implied warranty of
// MERCHANTABILITY or FITNESS FOR A PARTICULAR PURPOSE.  See the
// GNU General Public License for more details.
//
//
// Definitions for use in the dehacked code
//

#ifndef DEH_DEFS_H
#define DEH_DEFS_H

#include "sha1.h"

typedef struct deh_context_s deh_context_t;
typedef struct deh_section_s deh_section_t;
typedef void (*deh_section_init_t)(void);
typedef void *(*deh_section_start_t)(deh_context_t *context, char *line);
typedef void (*deh_section_end_t)(deh_context_t *context, void *tag);
typedef void (*deh_line_parser_t)(deh_context_t *context, char *line, void *tag);
typedef void (*deh_sha1_hash_t)(sha1_context_t *context);

struct deh_section_s
{
    char *name;

    // Called on startup to initialize code

    deh_section_init_t init;

    // This is called when a new section is started.  The pointer
    // returned is used as a tag for the following calls.

    deh_section_start_t start;

    // This is called for each line in the section

    deh_line_parser_t line_parser;

    // This is called at the end of the section for any cleanup

    deh_section_end_t end;

    // Called when generating an SHA1 sum of the dehacked state

    deh_sha1_hash_t sha1_hash;
};

#endif /* #ifndef DEH_DEFS_H */
```

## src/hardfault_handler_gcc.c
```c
/**
 * Copyright (c) 2015 - 2019, Nordic Semiconductor ASA
 *
 * All rights reserved.
 *
 * Redistribution and use in source and binary forms, with or without modification,
 * are permitted provided that the following conditions are met:
 *
 * 1. Redistributions of source code must retain the above copyright notice, this
 *    list of conditions and the following disclaimer.
 *
 * 2. Redistributions in binary form, except as embedded into a Nordic
 *    Semiconductor ASA integrated circuit in a product or a software update for
 *    such product, must reproduce the above copyright notice, this list of
 *    conditions and the following disclaimer in the documentation and/or other
 *    materials provided with the distribution.
 *
 * 3. Neither the name of Nordic Semiconductor ASA nor the names of its
 *    contributors may be used to endorse or promote products derived from this
 *    software without specific prior written permission.
 *
 * 4. This software, with or without modification, must only be used with a
 *    Nordic Semiconductor ASA integrated circuit.
 *
 * 5. Any software provided in binary form under this license must not be reverse
 *    engineered, decompiled, modified and/or disassembled.
 *
 * THIS SOFTWARE IS PROVIDED BY NORDIC SEMICONDUCTOR ASA "AS IS" AND ANY EXPRESS
 * OR IMPLIED WARRANTIES, INCLUDING, BUT NOT LIMITED TO, THE IMPLIED WARRANTIES
 * OF MERCHANTABILITY, NONINFRINGEMENT, AND FITNESS FOR A PARTICULAR PURPOSE ARE
 * DISCLAIMED. IN NO EVENT SHALL NORDIC SEMICONDUCTOR ASA OR CONTRIBUTORS BE
 * LIABLE FOR ANY DIRECT, INDIRECT, INCIDENTAL, SPECIAL, EXEMPLARY, OR
 * CONSEQUENTIAL DAMAGES (INCLUDING, BUT NOT LIMITED TO, PROCUREMENT OF SUBSTITUTE
 * GOODS OR SERVICES; LOSS OF USE, DATA, OR PROFITS; OR BUSINESS INTERRUPTION)
 * HOWEVER CAUSED AND ON ANY THEORY OF LIABILITY, WHETHER IN CONTRACT, STRICT
 * LIABILITY, OR TORT (INCLUDING NEGLIGENCE OR OTHERWISE) ARISING IN ANY WAY OUT
 * OF THE USE OF THIS SOFTWARE, EVEN IF ADVISED OF THE POSSIBILITY OF SUCH DAMAGE.
 *
 */
#include <stdint.h>
#include "compiler_abstraction.h"

extern void HardFault_c_handler(uint32_t *);

void HardFault_Handler(void) __attribute__(( naked ));

void HardFault_Handler(void)
{
    __ASM volatile(
    "   tst lr, #4                              \n"

    /* PSP is quite simple and does not require additional handler */
    "   itt ne                                  \n"
    "   mrsne r0, psp                           \n"
    /* Jump to the handler, do not store LR - returning from handler just exits exception */
    "   bne  HardFault_Handler_Continue         \n"

    /* Processing MSP requires stack checking */
    "   mrs r0, msp                             \n"

    "   ldr   r1, =__StackTop                   \n"
    "   ldr   r2, =__StackLimit                 \n"

    /* MSP is in the range of the stack area */
    "   cmp   r0, r1                            \n"
    "   bhi   HardFault_MoveSP                  \n"
    "   cmp   r0, r2                            \n"
    "   bhi   HardFault_Handler_Continue        \n"

    "HardFault_MoveSP:                          \n"
    "   mov   sp, r1                            \n"
    "   mov   r0, #0                            \n"

    "HardFault_Handler_Continue:                \n"
    "   ldr r3, =%0                             \n"
    "   bx r3                                   \n"
    "   .ltorg                                  \n"
    : : "X"(HardFault_c_handler)
    );
}
```

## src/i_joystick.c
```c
//
// Copyright(C) 2005-2014 Simon Howard
//
// This program is free software; you can redistribute it and/or
// modify it under the terms of the GNU General Public License
// as published by the Free Software Foundation; either version 2
// of the License, or (at your option) any later version.
//
// This program is distributed in the hope that it will be useful,
// but WITHOUT ANY WARRANTY; without even the implied warranty of
// MERCHANTABILITY or FITNESS FOR A PARTICULAR PURPOSE.  See the
// GNU General Public License for more details.
//
// DESCRIPTION:
//       Joystick code.
//

#include <stdlib.h>
#include <stdio.h>
#include <string.h>

#include "doomtype.h"
#include "d_event.h"
#include "i_joystick.h"
#include "i_system.h"

#include "m_config.h"
#include "m_misc.h"

// When an axis is within the dead zone, it is set to zero.
// This is 5% of the full range:

#define DEAD_ZONE (32768 / 3)

/* NRFD-TODO

static void *joystick = NULL;

// Configuration variables:

// Standard default.cfg Joystick enable/disable

static int usejoystick = 0;

// SDL GUID and index of the joystick to use.
static char *joystick_guid = "";
static int joystick_index = -1;

// Which joystick axis to use for horizontal movement, and whether to
// invert the direction:

static int joystick_x_axis = 0;
static int joystick_x_invert = 0;

// Which joystick axis to use for vertical movement, and whether to
// invert the direction:

static int joystick_y_axis = 1;
static int joystick_y_invert = 0;

// Which joystick axis to use for strafing?

static int joystick_strafe_axis = -1;
static int joystick_strafe_invert = 0;

// Which joystick axis to use for looking?

static int joystick_look_axis = -1;
static int joystick_look_invert = 0;

// Virtual to physical button joystick button mapping. By default this
// is a straight mapping.
static int joystick_physical_buttons[NUM_VIRTUAL_BUTTONS] = {
    0, 1, 2, 3, 4, 5, 6, 7, 8, 9, 10
};
void I_ShutdownJoystick(void)
{
    if (joystick != NULL)
    {
        joystick = NULL;
    }
}
*/

void I_InitJoystick(void)
{
    printf("NRFD_TODO: I_InitJoystick\n");

    // I_AtExit(I_ShutdownJoystick, true);
}

void I_UpdateJoystick(void)
{
        printf("NRFD_TODO: I_UpdateJoystick\n");
        /*

    if (joystick != NULL)
    {
        event_t ev;

        ev.type = ev_joystick;
        ev.data1 = GetButtonsState();
        ev.data2 = GetAxisState(joystick_x_axis, joystick_x_invert);
        ev.data3 = GetAxisState(joystick_y_axis, joystick_y_invert);
        ev.data4 = GetAxisState(joystick_strafe_axis, joystick_strafe_invert);
        ev.data5 = GetAxisState(joystick_look_axis, joystick_look_invert);

        D_PostEvent(&ev);
    }
        */
}

void I_BindJoystickVariables(void)
{
    int i;
    printf("NRFD-TODO: I_BindJoystickVariables\n");/*
    M_BindIntVariable("use_joystick",          &usejoystick);
    M_BindStringVariable("joystick_guid",      &joystick_guid);
    M_BindIntVariable("joystick_index",        &joystick_index);
    M_BindIntVariable("joystick_x_axis",       &joystick_x_axis);
    M_BindIntVariable("joystick_y_axis",       &joystick_y_axis);
    M_BindIntVariable("joystick_strafe_axis",  &joystick_strafe_axis);
    M_BindIntVariable("joystick_x_invert",     &joystick_x_invert);
    M_BindIntVariable("joystick_y_invert",     &joystick_y_invert);
    M_BindIntVariable("joystick_strafe_invert",&joystick_strafe_invert);
    M_BindIntVariable("joystick_look_axis",    &joystick_look_axis);
    M_BindIntVariable("joystick_look_invert",  &joystick_look_invert);

    for (i = 0; i < NUM_VIRTUAL_BUTTONS; ++i)
    {
        char name[32];
        M_snprintf(name, sizeof(name), "joystick_physical_button%i", i);
        M_BindIntVariable(name, &joystick_physical_buttons[i]);
    }
    */
}
```
